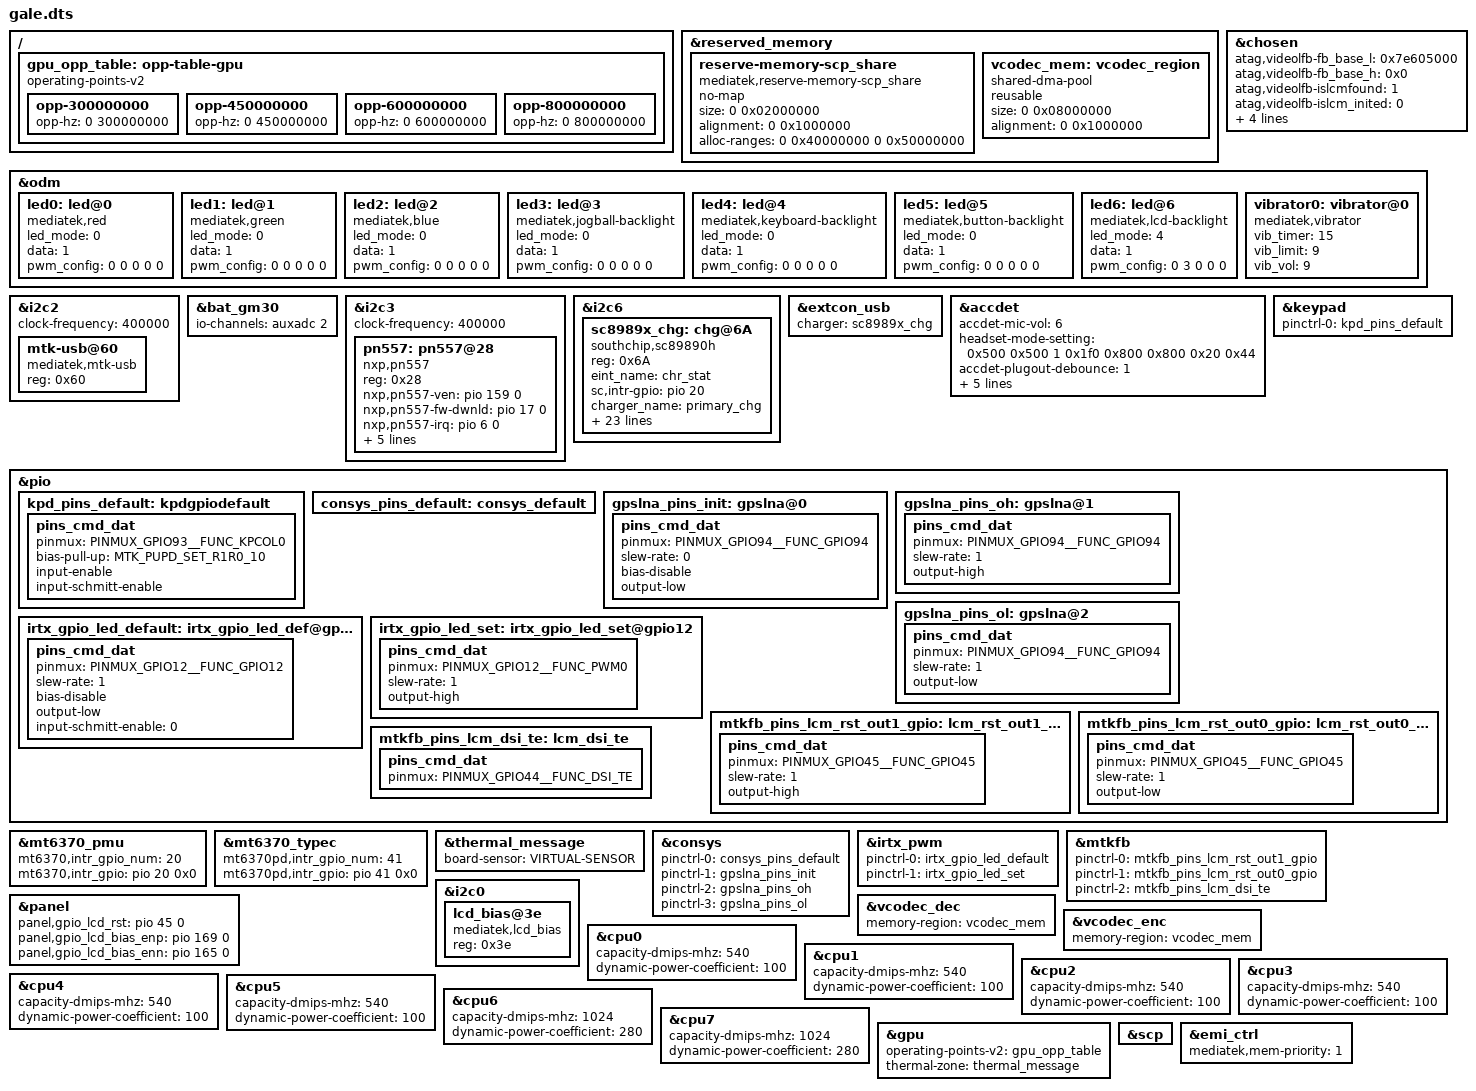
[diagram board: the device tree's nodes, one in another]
// SPDX-License-Identifier: GPL-2.0
/*
 * Copyright (c) 2019 MediaTek Inc.
 */

/dts-v1/;
/plugin/;
#include <dt-bindings/interrupt-controller/irq.h>
#include <dt-bindings/interrupt-controller/arm-gic.h>
#include <dt-bindings/pinctrl/mt6768-pinfunc.h>
#include "mediatek/touchscreen.dtsi"

&reserved_memory {
	reserve-memory-scp_share {
		compatible = "mediatek,reserve-memory-scp_share";
		no-map;
		size = <0 0x02000000>; /* [Dipertahankan] 32MB sesuai modifikasi empiris Anda */
		alignment = <0 0x1000000>;
		alloc-ranges = <0 0x40000000 0 0x50000000>;
	};

	/* [OPTIMASI] CMA Memori Dinamis untuk VCODEC */
	vcodec_mem: vcodec_region {
		compatible = "shared-dma-pool";
		reusable; 
		size = <0 0x08000000>; /* 128MB dinamis untuk akselerasi video */
		alignment = <0 0x1000000>;
	};
};

/* chosen */
&chosen {
	atag,videolfb-fb_base_l = <0x7e605000>;
	atag,videolfb-fb_base_h = <0x0>;
	atag,videolfb-islcmfound = <1>;
	atag,videolfb-islcm_inited = <0>;
	atag,videolfb-fps= <9000>; /* [OPTIMASI] 90Hz Framebuffer untuk transisi mulus */
	atag,videolfb-vramSize= <0x08000000>; /* [Dipertahankan] 128MB VRAM Hack untuk kelancaran HWC absolut */
	atag,videolfb-lcmname=
		"hx83112b_fhdp_dsi_cmd_auo_rt5081_drv";
};

&odm {
	led0:led@0 {
		compatible = "mediatek,red";
		led_mode = <0>;
		data = <1>;
		pwm_config = <0 0 0 0 0>;
	};
	led1:led@1 {
		compatible = "mediatek,green";
		led_mode = <0>;
		data = <1>;
		pwm_config = <0 0 0 0 0>;
	};
	led2:led@2 {
		compatible = "mediatek,blue";
		led_mode = <0>;
		data = <1>;
		pwm_config = <0 0 0 0 0>;
	};
	led3:led@3 {
		compatible = "mediatek,jogball-backlight";
		led_mode = <0>;
		data = <1>;
		pwm_config = <0 0 0 0 0>;
	};
	led4:led@4 {
		compatible = "mediatek,keyboard-backlight";
		led_mode = <0>;
		data = <1>;
		pwm_config = <0 0 0 0 0>;
	};
	led5:led@5 {
		compatible = "mediatek,button-backlight";
		led_mode = <0>;
		data = <1>;
		pwm_config = <0 0 0 0 0>;
	};
	led6:led@6 {
		compatible = "mediatek,lcd-backlight";
		led_mode = <4>;
		data = <1>;
		pwm_config = <0 3 0 0 0>;
	};
	vibrator0:vibrator@0 {
		compatible = "mediatek,vibrator";
		vib_timer = <15>; /* [OPTIMASI] Resonansi lebih tajam (Haptic Click) */
		vib_limit = <9>;
		vib_vol= <9>; /* Tegangan maksimal motor */
	};
};

/* --- I2C BUS (STANDAR, TIDAK DIUBAH) --- */
&i2c2 {
	clock-frequency = <400000>;
	mtk-usb@60 {
		compatible = "mediatek,mtk-usb";
		reg = <0x60>;
		status = "okay";
	};
};

&bat_gm30 {
	io-channels = <&auxadc 2>;
	io-channel-names = "batteryID-channel";
};

&i2c3 {
	status = "okay";
        clock-frequency = <400000>;
        pn557: pn557@28 {
		compatible = "nxp,pn557";
		reg = <0x28>;
		nxp,pn557-ven = <&pio 159 0>;
		nxp,pn557-fw-dwnld = <&pio 17 0>;
		nxp,pn557-irq = <&pio 6 0>;
		interrupt-parent = <&pio>;
		interrupts = <6 IRQ_TYPE_LEVEL_LOW>;
		tms,irq-gpio        = <&pio 6 0x00>;
		tms,ven-gpio        = <&pio 159 0x0>;
		tms,download-gpio   = <&pio 17 0x0>;
		status = "okay";
        };
};

&i2c6 {
	status = "okay";
	sc8989x_chg: chg@6A {
			compatible = "southchip,sc89890h";
			reg = <0x6A>;
			eint_name = "chr_stat";
			sc,intr-gpio = <&pio 20 IRQ_TYPE_EDGE_FALLING>;
			charger_name = "primary_chg";
			sc,sc8989x,ico-en = <0>;
			sc,sc8989x,hvdcp-en = <1>;
			sc,sc8989x,auto-dpdm-en = <0>;
			sc,sc8989x,vsys-min = <5>;
			sc,sc8989x,vbatmin-sel = <0>;
			sc,sc8989x,itrick = <3>; 
			sc,sc8989x,iterm = <4>; 
			sc,sc8989x,vbat-cv = <38>;
			sc,sc8989x,vbat-low = <1>;
			sc,sc8989x,vrechg = <0>;
			sc,sc8989x,en-term = <1>;
			sc,sc8989x,stat-dis = <0>;
			sc,sc8989x,wd-time = <0>; 
			sc,sc8989x,en-timer = <1>;
			sc,sc8989x,charge-timer = <2>;
			sc,sc8989x,bat-comp = <0>;
			sc,sc8989x,vclamp = <0>; 
			sc,sc8989x,votg = <10>; 
			sc,sc8989x,iboost = <7>;
			sc,sc8989x,vindpm = <20>; 

			/*bq25890*/
			bq,bq25890,votg = <7>; 
			bq,bq25890,iterm = <3>;
			bq,bq25890,itrick = <3>; 
	};
};

&extcon_usb {
	charger = <&sc8989x_chg>;
};

/* accdet start */
&accdet {
	accdet-mic-vol = <6>;
	headset-mode-setting = <0x500 0x500 1 0x1f0 0x800 0x800 0x20 0x44>;
	accdet-plugout-debounce = <1>;
	accdet-mic-mode = <1>;
	headset-eint-level-pol = <8>;
	headset-three-key-threshold = <0 80 220 400>;
	headset-three-key-threshold-CDD = <0 121 192 600>;
	headset-four-key-threshold = <0 58 121 192 400>;
	status = "okay";
};
/* accdet end */

/* keypad start */
&keypad {
	pinctrl-names = "default";
	pinctrl-0 = <&kpd_pins_default>;
};
&pio {
	kpd_pins_default: kpdgpiodefault {
		pins_cmd_dat {
			pinmux = <PINMUX_GPIO93__FUNC_KPCOL0>;
			bias-pull-up = <MTK_PUPD_SET_R1R0_10>;
			input-enable;
			input-schmitt-enable;
		};
	};
};
/* keypad end */

&mt6370_pmu {
	mt6370,intr_gpio_num = <20>; 
	mt6370,intr_gpio = <&pio 20 0x0>;
};
&mt6370_typec {
	mt6370pd,intr_gpio_num = <41>; 
	mt6370pd,intr_gpio = <&pio 41 0x0>;
};

&thermal_message {
	board-sensor = "VIRTUAL-SENSOR";
};

/* CONSYS GPIO standardization */
&pio {
	consys_pins_default: consys_default {
	};
	gpslna_pins_init: gpslna@0 {
		pins_cmd_dat {
			pinmux = <PINMUX_GPIO94__FUNC_GPIO94>;
			slew-rate = <0>;
			bias-disable;
			output-low;
		};
	};
	gpslna_pins_oh: gpslna@1 {
		pins_cmd_dat {
			pinmux = <PINMUX_GPIO94__FUNC_GPIO94>;
			slew-rate = <1>;
			output-high;
		};
	};
	gpslna_pins_ol: gpslna@2 {
		pins_cmd_dat {
			pinmux = <PINMUX_GPIO94__FUNC_GPIO94>;
			slew-rate = <1>;
			output-low;
		};
	};
};
&consys {
	pinctrl-names = "default", "gps_lna_state_init",
		"gps_lna_state_oh", "gps_lna_state_ol";
	pinctrl-0 = <&consys_pins_default>;
	pinctrl-1 = <&gpslna_pins_init>;
	pinctrl-2 = <&gpslna_pins_oh>;
	pinctrl-3 = <&gpslna_pins_ol>;
	status = "okay";
};
/* CONSYS end */

/* IRTX GPIO Start */
&irtx_pwm {
	pinctrl-names = "irtx_gpio_led_default", "irtx_gpio_led_set";
	pinctrl-0 = <&irtx_gpio_led_default>;
	pinctrl-1 = <&irtx_gpio_led_set>;
	status = "okay";
};
&pio {
	irtx_gpio_led_default:irtx_gpio_led_def@gpio12 {
		pins_cmd_dat {
			pinmux = <PINMUX_GPIO12__FUNC_GPIO12>;
			slew-rate = <1>;
			bias-disable;
			output-low;
			input-schmitt-enable = <0>;
		};
	};

	irtx_gpio_led_set:irtx_gpio_led_set@gpio12 {
		pins_cmd_dat {
			pinmux = <PINMUX_GPIO12__FUNC_PWM0>;
			slew-rate = <1>;
			output-high;
		};
	};
}; /* IRTX GPIO Settings -End */

/* DISPSYS GPIO standardization */
&pio {
	mtkfb_pins_lcm_rst_out1_gpio: lcm_rst_out1_gpio {
		pins_cmd_dat {
			pinmux = <PINMUX_GPIO45__FUNC_GPIO45>;
			slew-rate = <1>;
			output-high;
		};
	};

	mtkfb_pins_lcm_rst_out0_gpio: lcm_rst_out0_gpio {
		pins_cmd_dat {
			pinmux = <PINMUX_GPIO45__FUNC_GPIO45>;
			slew-rate = <1>;
			output-low;
		};
	};
	mtkfb_pins_lcm_dsi_te: lcm_dsi_te {
		pins_cmd_dat {
			pinmux = <PINMUX_GPIO44__FUNC_DSI_TE>;
		};
	};
};

&mtkfb {
	pinctrl-names =
		"lcm_rst_out1_gpio", "lcm_rst_out0_gpio",
		"mode_te_te";
	pinctrl-0 = <&mtkfb_pins_lcm_rst_out1_gpio>;
	pinctrl-1 = <&mtkfb_pins_lcm_rst_out0_gpio>;
	pinctrl-2 = <&mtkfb_pins_lcm_dsi_te>;
	status = "okay";
};

&panel{
	panel,gpio_lcd_rst = <&pio 45 0>;
	panel,gpio_lcd_bias_enp = <&pio 169 0>;
	panel,gpio_lcd_bias_enn = <&pio 165 0>;
};

&i2c0{

	lcd_bias@3e {
		compatible = "mediatek,lcd_bias";
		reg = <0x3e>;
		status = "okay";
	};
};
/* DISPSYS GPIO standardization end*/


/* ==========================================================
 * BLOK OPTIMASI ARSITEKTUR KOMPREHENSIF
 * ========================================================== */

/* --- 1. [OPTIMASI MEMORI] VCODEC CMA Link --- */
&vcodec_dec { memory-region = <&vcodec_mem>; };
&vcodec_enc { memory-region = <&vcodec_mem>; };

/* --- 2. [OPTIMASI CPU] Energy Aware Scheduling --- */
&cpu0 { capacity-dmips-mhz = <540>; dynamic-power-coefficient = <100>; };
&cpu1 { capacity-dmips-mhz = <540>; dynamic-power-coefficient = <100>; };
&cpu2 { capacity-dmips-mhz = <540>; dynamic-power-coefficient = <100>; };
&cpu3 { capacity-dmips-mhz = <540>; dynamic-power-coefficient = <100>; };
&cpu4 { capacity-dmips-mhz = <540>; dynamic-power-coefficient = <100>; };
&cpu5 { capacity-dmips-mhz = <540>; dynamic-power-coefficient = <100>; };
&cpu6 { capacity-dmips-mhz = <1024>; dynamic-power-coefficient = <280>; };
&cpu7 { capacity-dmips-mhz = <1024>; dynamic-power-coefficient = <280>; };

/* --- 3. [OPTIMASI GPU] OPP Kurva Termal & Link Sensor --- */
/ {
	gpu_opp_table: opp-table-gpu {
		compatible = "operating-points-v2";
		opp-300000000 { opp-hz = <0 300000000>; };
		opp-450000000 { opp-hz = <0 450000000>; };
		opp-600000000 { opp-hz = <0 600000000>; };
		opp-800000000 { opp-hz = <0 800000000>; };
	};
};

&gpu {
	operating-points-v2 = <&gpu_opp_table>;
	#cooling-cells = <2>;
	thermal-zone = <&thermal_message>;
	status = "okay";
};

/* --- 4. [OPTIMASI SCP] Hardware Offloading --- */
&scp { status = "okay"; };

/* --- 5. [OPTIMASI QoS] Prioritas EMI Tinggi --- */
&emi_ctrl {
	mediatek,mem-priority = <1>; 
	status = "okay";
};
/* ========================================================== */

#include <mediatek/gale/cust.dtsi>
#include "mediatek/cust_mt6768_camera.dtsi"
//#include "mediatek/cust_mt6768_touch_1080x2160.dtsi"
#include "mediatek/foursemi-fs15xx.dtsi"
#include "mediatek/fingerprint.dtsi"
/*End of this file, DO NOT ADD ANYTHING HERE*/
